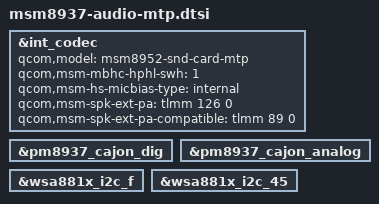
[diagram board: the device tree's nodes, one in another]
/*
 * Copyright (c) 2015-2016, The Linux Foundation. All rights reserved.
 *
 * This program is free software; you can redistribute it and/or modify
 * it under the terms of the GNU General Public License version 2 and
 * only version 2 as published by the Free Software Foundation.
 *
 * This program is distributed in the hope that it will be useful,
 * but WITHOUT ANY WARRANTY; without even the implied warranty of
 * MERCHANTABILITY or FITNESS FOR A PARTICULAR PURPOSE.  See the
 * GNU General Public License for more details.
 */

&int_codec {
	status = "okay";
	qcom,model = "msm8952-snd-card-mtp";
	qcom,msm-mbhc-hphl-swh = <1>;
	qcom,msm-hs-micbias-type = "internal";
	qcom,msm-spk-ext-pa = <&tlmm 126 0>;
	qcom,msm-spk-ext-pa-compatible = <&tlmm 89 0>;
};

&pm8937_cajon_dig {
	status = "okay";
};

&pm8937_cajon_analog {
	status = "okay";
};

&wsa881x_i2c_f {
	status = "okay";
};

&wsa881x_i2c_45 {
	status = "okay";
};
